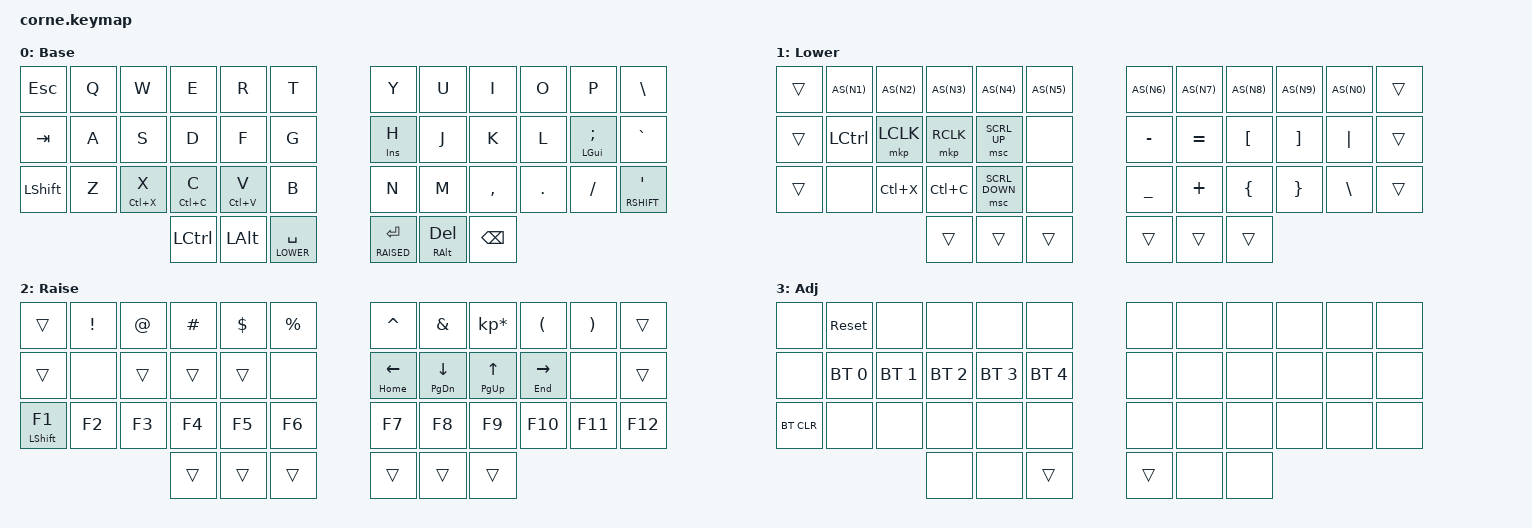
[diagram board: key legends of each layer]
 /*
 * Copyright (c) 2020 The ZMK Contributors
 *
 * SPDX-License-Identifier: MIT
 */

#include <behaviors.dtsi>
#include <dt-bindings/zmk/keys.h>
#include <dt-bindings/zmk/bt.h>
#include <dt-bindings/zmk/ext_power.h>
#include <dt-bindings/zmk/pointing.h>
#include "config.h"
#define ADJUST 3
#include "my-behaviours.dtsi"
/ {

    keymap {
            compatible = "zmk,keymap";
            default_layer {
// -----------------------------------------------------------------------------------------
// | ESC  |  Q  |  W  |  E  |  R  |  T  |   |  Y  |  U   |  I  |  O  |  P   |   \  |
// | TAB  |  A  |  S  |  D  |  F  |  G  |   |  H  |  J   |  K  |  L  |;/lgui|  `   |
// | SHFT |  Z  |  X  |  C  |  V  |  B  |   |  N  |  M   |  ,  |  .  |  /   |  ' |
//                    | CTL | ALT |SPC/LWR| |ENT/RSE| ALT/DEL | BSPC |
                        display-name = "Base";
                        bindings = <
     &kp ESC     &kp Q       &kp W          &kp E       &kp R        &kp T           &kp Y        &kp U        &kp I        &kp O        &kp P      &kp BSLH
     &kp TAB     &kp A       &kp S          &kp D       &kp F        &kp G           &ht INSERT H &kp J        &kp K        &kp L        &ht LGUI SEMI &kp GRAVE   
     &kp LSHFT   &kp Z       &ht LC(X) X    &ht LC(C) C &ht LC(V) V  &kp B           &kp N        &kp M        &kp COMMA    &kp DOT      &kp FSLH   &lt RSHIFT SQT
                                            &kp LCTRL   &kp LALT   &lt LOWER SPACE &lt RAISED RET  &mt RALT DEL &kp BSPC
                        >;
                };
            lower_layer {
// -----------------------------------------------------------------------------------------
// |  ESC |  1  |  2  |  3  |  4  |  5  |   |  6  |  7  |  8  |  9  |  0  |   \  |
// | TAB  | xxx |lctrl| LALT|LSHT | xxx |   |  -  |  =  |  [  |  ]  |  \  |  `   |
// | SHFT |     |     | xxx | xxx | xxx |   |  _  |  +  |  {  |  }  | "|" |  ~   |
//                    | CTL | ALT | SPC |   | ENT | ALT/DEL | BSPC |
                        display-name = "Lower";
                        bindings = <
     &trans      AS(N1)         AS(N2)         AS(N3)        AS(N4)            AS(N5)            AS(N6)        AS(N7)            AS(N8)             AS(N9)           AS(N0)     &trans 
     &trans      &kp LCTRL      &mkp LCLK      &mkp RCLK       &msc SCRL_UP    &none             &kp MINUS     &kp EQUAL         &kp LBKT           &kp RBKT         &kp PIPE   &trans
     &trans      &none          &kp LC(X)      &kp LC(C)       &msc SCRL_DOWN  &none             &kp UNDER     &kp PLUS          &kp LBRC           &kp RBRC         &kp BSLH   &trans
                                               &trans          &trans          &trans            &trans        &trans            &trans
                        >;
            };

            raise_layer {
// -----------------------------------------------------------------------------------------
// |  ESC |  !  |  @  |  #  |  $  |  %  |   |  ^  |  &  |  *  |  (  |  )  |   \  |
// | TAB  | xx  |lctrl| LALT|LSHT | xxx |   | LFT | DWN |  UP | RGT |     |  `   |
// |F1/SHT| F2  | F3  | F4  | F5  | F6  |   | F7  | F8  |  F9 | F10 | F11 |  F12 |
//                    | CTL | ALT | SPC |   | ENT |     | ALT |
                        display-name = "Raise";
                        bindings = <
      &trans          &kp EXCL     &kp AT       &kp HASH     &kp DLLR    &kp PRCNT      &kp CARET     &kp AMPS       &kp KP_MULTIPLY &kp LPAR      &kp RPAR    &trans
      &trans          &none        &trans       &trans       &trans      &none          &ht HOME LEFT &ht PG_DN DOWN &ht PG_UP UP    &ht END RIGHT &none       &trans
      &ht LSHFT F1    &kp F2       &kp F3       &kp F4       &kp F5      &kp F6         &kp F7        &kp F8         &kp F9          &kp F10       &kp F11     &kp F12
                                                &trans       &trans      &trans         &trans        &trans         &trans
                        >;
            };

            adjust_layer {
// -----------------------------------------------------------------------------------------
// |      | RST |     |     |     |     |   |     |     |     |     |     |      |
// |      | BT1 | BT2 | BT3 | BT4 | BT5 |   |     |     |     |     |     |      |
// | CLR  |     |     |     |     |     |   |     |     |     |     |     |      |
//                    |     |     | SPC |   | ENT |     |     |
                        display-name = "Adj";
                        bindings = <

   &none         &sys_reset   &none        &none        &none        &none        &none      &none        &none      &none        &none    &none
   &none         &bt BT_SEL 0 &bt BT_SEL 1 &bt BT_SEL 2 &bt BT_SEL 3 &bt BT_SEL 4 &none      &none        &none      &none        &none    &none
   &bt BT_CLR    &none        &none        &none        &none        &none        &none      &none        &none      &none        &none    &none 
                                           &none        &none        &trans       &trans     &none        &none  
                        >;                  
                };
     };
     
};
